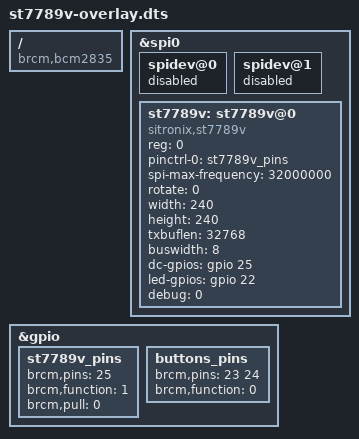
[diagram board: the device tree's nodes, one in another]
/dts-v1/;
/plugin/;

/ {
	compatible = "brcm,bcm2835", "brcm,bcm2708", "brcm,bcm2709";

	fragment@0 {
		target = <&spi0>;
		__overlay__ {
			status = "okay";

			spidev@0 {
				status = "disabled";
			};

			spidev@1 {
				status = "disabled";
			};
		};
	};

	fragment@1 {
	        target = <&gpio>;
	        __overlay__ {
	                st7789v_pins: st7789v_pins {
	                        brcm,pins = <25>;
	                        brcm,function = <1>;
				brcm,pull = <0>;
	                };

	                buttons_pins: buttons_pins {
	                        brcm,pins = <23 24>;
	                        brcm,function = <0>;
	                };
	        };
	};

	fragment@2 {
	        target = <&spi0>;
	        __overlay__ {
	                #address-cells = <1>;
	                #size-cells = <0>;

	                st7789v: st7789v@0 {
	                        compatible = "sitronix,st7789v";
	                        reg = <0>;
	                        pinctrl-names = "default";
	                        pinctrl-0 = <&st7789v_pins>;
	                        spi-max-frequency = <32000000>;
	                        rotate = <0>;
	                        width = <240>;
	                        height = <240>;
				txbuflen = <32768>;
				buswidth = <8>;
	                        dc-gpios = <&gpio 25 0>;
	                        led-gpios = <&gpio 22 0>;
	                        debug = <0>;
	                };
	        };
	};

	__overrides__ {
	        speed = <&st7789v>,"spi-max-frequency:0";
	        rotate = <&st7789v>,"rotate:0";
	        width = <&st7789v>,"width:0";
	        height = <&st7789v>,"height:0";
	        fps = <&st7789v>,"fps:0";
	        debug = <&st7789v>,"debug:0";
	};
};
